AUTOSAR XML (schema 00047)
package /Svc_IoHwAb/ClientServerInterfaces
  5 x client server interface, all with is-service=true:
    IoHwAb_If_AnaInDir
      operation ReadDirect: possible-error=[E_BUSY, E_SETUP_BUFFER_FAIL, E_WRONG_LENGTH]
        arg Value: type=IoHwAb_ValueType, direction=OUT, server-argument-impl-policy=USE-ARGUMENT-TYPE
        arg AnaInDirLength: type=IoHwAb_LengthType, direction=IN, server-argument-impl-policy=USE-ARGUMENT-TYPE
      error E_BUSY: error-code=4
      error E_SETUP_BUFFER_FAIL: error-code=6
      error E_WRONG_LENGTH: error-code=5
    IoHwAb_If_DigDir
      6 x operation:
        IsInput
          arg blResult: type=IoHwAb_BoolType, direction=OUT, server-argument-impl-policy=USE-ARGUMENT-TYPE
        IsOutput
          arg blResult: type=IoHwAb_BoolType, direction=OUT, server-argument-impl-policy=USE-ARGUMENT-TYPE
        ReadDirect
          arg Level: type=IoHwAb_LevelType, direction=OUT, server-argument-impl-policy=USE-ARGUMENT-TYPE
        SetToInput
        SetToOutput
        WriteDirect
          arg Level: type=IoHwAb_LevelType, direction=IN, server-argument-impl-policy=USE-ARGUMENT-TYPE
    IoHwAb_If_Gpt
      7 x operation:
        DisableNotification: possible-error=IoHwAb_If_Gpt/E_NOT_SUPPORTED
        EnableNotification: possible-error=IoHwAb_If_Gpt/E_NOT_SUPPORTED
        GetTimeElapsed: possible-error=IoHwAb_If_Gpt/E_NOT_SUPPORTED
          arg Value: type=IoHwAb_GptValueType, direction=OUT, server-argument-impl-policy=USE-ARGUMENT-TYPE
        GetTimeRemaining: possible-error=IoHwAb_If_Gpt/E_NOT_SUPPORTED
          arg Value: type=IoHwAb_GptValueType, direction=OUT, server-argument-impl-policy=USE-ARGUMENT-TYPE
        Notification
        StartTimer: possible-error=IoHwAb_If_Gpt/E_NOT_SUPPORTED
          arg Value: type=IoHwAb_GptValueType, direction=IN, server-argument-impl-policy=USE-ARGUMENT-TYPE
        StopTimer: possible-error=IoHwAb_If_Gpt/E_NOT_SUPPORTED
      error E_NOT_SUPPORTED: error-code=10
    IoHwAb_If_Icu
      18 x operation:
        DisableEdgeCount: possible-error=IoHwAb_If_Icu/E_NOT_SUPPORTED
        DisableEdgeDetection: possible-error=IoHwAb_If_Icu/E_NOT_SUPPORTED
        DisableNotification: possible-error=IoHwAb_If_Icu/E_NOT_SUPPORTED
        EnableEdgeCount: possible-error=IoHwAb_If_Icu/E_NOT_SUPPORTED
        EnableEdgeDetection: possible-error=IoHwAb_If_Icu/E_NOT_SUPPORTED
        EnableNotification: possible-error=IoHwAb_If_Icu/E_NOT_SUPPORTED
        GetDutyCycleValues: possible-error=IoHwAb_If_Icu/E_NOT_SUPPORTED
          arg DutyCycle: type=IoHwAb_IcuDutyCycleType, direction=OUT, server-argument-impl-policy=USE-ARGUMENT-TYPE
        GetEdgeNumbers: possible-error=IoHwAb_If_Icu/E_NOT_SUPPORTED
          arg Num: type=IoHwAb_IcuEdgeNumberType, direction=OUT, server-argument-impl-policy=USE-ARGUMENT-TYPE
        GetInputState: possible-error=IoHwAb_If_Icu/E_NOT_SUPPORTED
          arg State: type=IoHwAb_IcuStateType, direction=OUT, server-argument-impl-policy=USE-ARGUMENT-TYPE
        GetTimeElapsed: possible-error=IoHwAb_If_Icu/E_NOT_SUPPORTED
          arg Time: type=IoHwAb_IcuValueType, direction=OUT, server-argument-impl-policy=USE-ARGUMENT-TYPE
        GetTimestampIndex: possible-error=IoHwAb_If_Icu/E_NOT_SUPPORTED
          arg TimestampIdx: type=IoHwAb_IcuIndexType, direction=OUT, server-argument-impl-policy=USE-ARGUMENT-TYPE
        Notification
        ResetEdgeCount: possible-error=IoHwAb_If_Icu/E_NOT_SUPPORTED
        SetActivationCondition: possible-error=IoHwAb_If_Icu/E_NOT_SUPPORTED
          arg Activation: type=IoHwAb_IcuActivationType, direction=IN, server-argument-impl-policy=USE-ARGUMENT-TYPE
        StartSignalMeasurement: possible-error=IoHwAb_If_Icu/E_NOT_SUPPORTED
        StartTimestamp: possible-error=IoHwAb_If_Icu/E_NOT_SUPPORTED
          arg BufPtr: type=IoHwAb_IcuValueType, direction=OUT, server-argument-impl-policy=USE-ARGUMENT-TYPE
          arg BufSize: type=uint16, direction=IN, server-argument-impl-policy=USE-ARGUMENT-TYPE
          arg NotiItv: type=uint16, direction=IN, server-argument-impl-policy=USE-ARGUMENT-TYPE
        StopSignalMeasurement: possible-error=IoHwAb_If_Icu/E_NOT_SUPPORTED
        StopTimestamp: possible-error=IoHwAb_If_Icu/E_NOT_SUPPORTED
      error E_NOT_SUPPORTED: error-code=9
    IoHwAb_If_Pwm
      5 x operation, all with possible-error=IoHwAb_If_Pwm/E_NOT_SUPPORTED:
        DisableNotification
        EnableNotification
          arg NotificationEdge: type=IoHwAb_PwmEdgeType, direction=IN, server-argument-impl-policy=USE-ARGUMENT-TYPE
        SetDutyCycle
          arg Duty: type=uint16, direction=IN, server-argument-impl-policy=USE-ARGUMENT-TYPE
        SetOutputToIdle
        SetPeriodAndDuty
          arg Period: type=IoHwAb_PwmPeriodType, direction=IN, server-argument-impl-policy=USE-ARGUMENT-TYPE
          arg Duty: type=uint16, direction=IN, server-argument-impl-policy=USE-ARGUMENT-TYPE
      error E_NOT_SUPPORTED: error-code=11
package /Svc_IoHwAb/CompuMethods
  compu method IoHwAb_Cm_EdgeEnum: 1=IOHWAB_RISING_EDGE (IoHwAb_RisingEdge), 2=IOHWAB_FALLING_EDGE (IoHwAb_FallingEdge), 3=IOHWAB_BOTH_EDGES (IoHwAb_BothEdges)
package /Svc_IoHwAb/EcuAbstractionSwComponentTypes
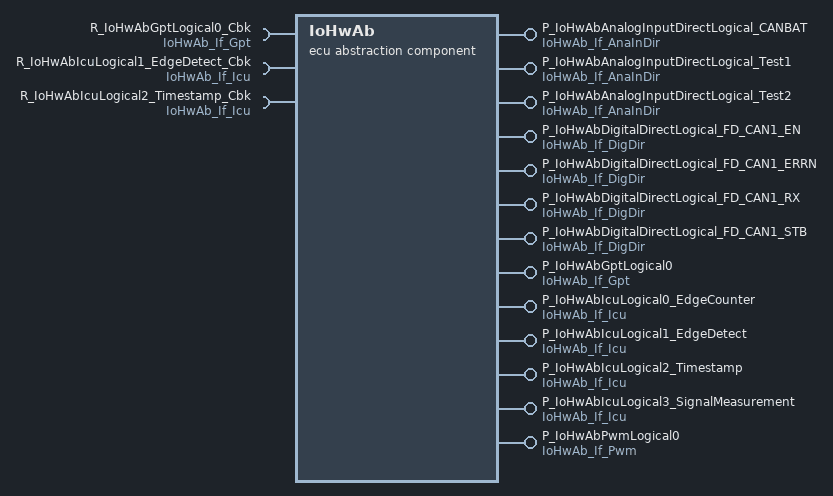
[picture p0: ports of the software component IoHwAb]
  ecu abstraction sw component type IoHwAb
    13 x provide port:
      P_IoHwAbAnalogInputDirectLogical_CANBAT: server-com-spec{operation=IoHwAb_If_AnaInDir/ReadDirect, queue-length=1}, provided-interface=IoHwAb_If_AnaInDir
      P_IoHwAbAnalogInputDirectLogical_Test1: server-com-spec{operation=IoHwAb_If_AnaInDir/ReadDirect, queue-length=1}, provided-interface=IoHwAb_If_AnaInDir
      P_IoHwAbAnalogInputDirectLogical_Test2: server-com-spec{operation=IoHwAb_If_AnaInDir/ReadDirect, queue-length=1}, provided-interface=IoHwAb_If_AnaInDir
      P_IoHwAbDigitalDirectLogical_FD_CAN1_EN: provided-interface=IoHwAb_If_DigDir
        provided-com-specs:
          operation=SetToInput, queue-length=1
          operation=SetToOutput, queue-length=1
          operation=IoHwAb_If_DigDir/ReadDirect, queue-length=1
          operation=WriteDirect, queue-length=1
          operation=IsOutput, queue-length=1
          operation=IsInput, queue-length=1
      P_IoHwAbDigitalDirectLogical_FD_CAN1_ERRN: provided-interface=IoHwAb_If_DigDir
        provided-com-specs:
          operation=SetToInput, queue-length=1
          operation=SetToOutput, queue-length=1
          operation=IoHwAb_If_DigDir/ReadDirect, queue-length=1
          operation=WriteDirect, queue-length=1
          operation=IsOutput, queue-length=1
          operation=IsInput, queue-length=1
      P_IoHwAbDigitalDirectLogical_FD_CAN1_RX: provided-interface=IoHwAb_If_DigDir
        provided-com-specs:
          operation=SetToInput, queue-length=1
          operation=SetToOutput, queue-length=1
          operation=IoHwAb_If_DigDir/ReadDirect, queue-length=1
          operation=WriteDirect, queue-length=1
          operation=IsOutput, queue-length=1
          operation=IsInput, queue-length=1
      P_IoHwAbDigitalDirectLogical_FD_CAN1_STB: provided-interface=IoHwAb_If_DigDir
        provided-com-specs:
          operation=SetToInput, queue-length=1
          operation=SetToOutput, queue-length=1
          operation=IoHwAb_If_DigDir/ReadDirect, queue-length=1
          operation=WriteDirect, queue-length=1
          operation=IsOutput, queue-length=1
          operation=IsInput, queue-length=1
      P_IoHwAbGptLogical0: provided-interface=IoHwAb_If_Gpt
        provided-com-specs:
          operation=StopTimer, queue-length=1
          operation=IoHwAb_If_Gpt/DisableNotification, queue-length=1
          operation=IoHwAb_If_Gpt/GetTimeElapsed, queue-length=1
          operation=IoHwAb_If_Gpt/EnableNotification, queue-length=1
          operation=StartTimer, queue-length=1
          operation=GetTimeRemaining, queue-length=1
      P_IoHwAbIcuLogical0_EdgeCounter: provided-interface=IoHwAb_If_Icu
        provided-com-specs:
          operation=GetInputState, queue-length=1
          operation=IoHwAb_If_Icu/DisableNotification, queue-length=1
          operation=StartTimestamp, queue-length=1
          operation=IoHwAb_If_Icu/GetTimeElapsed, queue-length=1
          operation=DisableEdgeCount, queue-length=1
          operation=EnableEdgeDetection, queue-length=1
          operation=GetDutyCycleValues, queue-length=1
          operation=ResetEdgeCount, queue-length=1
          operation=StopTimestamp, queue-length=1
          operation=StartSignalMeasurement, queue-length=1
          operation=IoHwAb_If_Icu/EnableNotification, queue-length=1
          operation=GetTimestampIndex, queue-length=1
          operation=GetEdgeNumbers, queue-length=1
          operation=DisableEdgeDetection, queue-length=1
          operation=SetActivationCondition, queue-length=1
          operation=EnableEdgeCount, queue-length=1
          operation=StopSignalMeasurement, queue-length=1
      P_IoHwAbIcuLogical1_EdgeDetect: provided-interface=IoHwAb_If_Icu
        provided-com-specs:
          operation=GetInputState, queue-length=1
          operation=IoHwAb_If_Icu/DisableNotification, queue-length=1
          operation=StartTimestamp, queue-length=1
          operation=IoHwAb_If_Icu/GetTimeElapsed, queue-length=1
          operation=DisableEdgeCount, queue-length=1
          operation=EnableEdgeDetection, queue-length=1
          operation=GetDutyCycleValues, queue-length=1
          operation=ResetEdgeCount, queue-length=1
          operation=StopTimestamp, queue-length=1
          operation=StartSignalMeasurement, queue-length=1
          operation=IoHwAb_If_Icu/EnableNotification, queue-length=1
          operation=GetTimestampIndex, queue-length=1
          operation=GetEdgeNumbers, queue-length=1
          operation=DisableEdgeDetection, queue-length=1
          operation=SetActivationCondition, queue-length=1
          operation=EnableEdgeCount, queue-length=1
          operation=StopSignalMeasurement, queue-length=1
      P_IoHwAbIcuLogical2_Timestamp: provided-interface=IoHwAb_If_Icu
        provided-com-specs:
          operation=GetInputState, queue-length=1
          operation=IoHwAb_If_Icu/DisableNotification, queue-length=1
          operation=StartTimestamp, queue-length=1
          operation=IoHwAb_If_Icu/GetTimeElapsed, queue-length=1
          operation=DisableEdgeCount, queue-length=1
          operation=EnableEdgeDetection, queue-length=1
          operation=GetDutyCycleValues, queue-length=1
          operation=ResetEdgeCount, queue-length=1
          operation=StopTimestamp, queue-length=1
          operation=StartSignalMeasurement, queue-length=1
          operation=IoHwAb_If_Icu/EnableNotification, queue-length=1
          operation=GetTimestampIndex, queue-length=1
          operation=GetEdgeNumbers, queue-length=1
          operation=DisableEdgeDetection, queue-length=1
          operation=SetActivationCondition, queue-length=1
          operation=EnableEdgeCount, queue-length=1
          operation=StopSignalMeasurement, queue-length=1
      P_IoHwAbIcuLogical3_SignalMeasurement: provided-interface=IoHwAb_If_Icu
        provided-com-specs:
          operation=GetInputState, queue-length=1
          operation=IoHwAb_If_Icu/DisableNotification, queue-length=1
          operation=StartTimestamp, queue-length=1
          operation=IoHwAb_If_Icu/GetTimeElapsed, queue-length=1
          operation=DisableEdgeCount, queue-length=1
          operation=EnableEdgeDetection, queue-length=1
          operation=GetDutyCycleValues, queue-length=1
          operation=ResetEdgeCount, queue-length=1
          operation=StopTimestamp, queue-length=1
          operation=StartSignalMeasurement, queue-length=1
          operation=IoHwAb_If_Icu/EnableNotification, queue-length=1
          operation=GetTimestampIndex, queue-length=1
          operation=GetEdgeNumbers, queue-length=1
          operation=DisableEdgeDetection, queue-length=1
          operation=SetActivationCondition, queue-length=1
          operation=EnableEdgeCount, queue-length=1
          operation=StopSignalMeasurement, queue-length=1
      P_IoHwAbPwmLogical0: provided-interface=IoHwAb_If_Pwm
        provided-com-specs:
          operation=SetDutyCycle, queue-length=1
          operation=IoHwAb_If_Pwm/DisableNotification, queue-length=1
          operation=SetPeriodAndDuty, queue-length=1
          operation=IoHwAb_If_Pwm/EnableNotification, queue-length=1
          operation=SetOutputToIdle, queue-length=1
    require port R_IoHwAbGptLogical0_Cbk: client-com-spec=IoHwAb_If_Gpt/Notification, required-interface=IoHwAb_If_Gpt
    require port R_IoHwAbIcuLogical1_EdgeDetect_Cbk: client-com-spec=IoHwAb_If_Icu/Notification, required-interface=IoHwAb_If_Icu
    require port R_IoHwAbIcuLogical2_Timestamp_Cbk: client-com-spec=IoHwAb_If_Icu/Notification, required-interface=IoHwAb_If_Icu
    behavior IB_IoHwAb: handle-termination-and-restart=NO-SUPPORT
      106 x operation invoked event:
        IoHwAb_Ev_IoHwAbAnalogInputDirectLogical_CANBAT_ReadDirect: start-on-event=IoHwAb_Re_AnaInDir_ReadDirect, operation=P_IoHwAbAnalogInputDirectLogical_CANBAT.ReadDirect
        IoHwAb_Ev_IoHwAbAnalogInputDirectLogical_Test1_ReadDirect: start-on-event=IoHwAb_Re_AnaInDir_ReadDirect, operation=P_IoHwAbAnalogInputDirectLogical_Test1.ReadDirect
        IoHwAb_Ev_IoHwAbAnalogInputDirectLogical_Test2_ReadDirect: start-on-event=IoHwAb_Re_AnaInDir_ReadDirect, operation=P_IoHwAbAnalogInputDirectLogical_Test2.ReadDirect
        IoHwAb_Ev_IoHwAbDigitalDirectLogical_FD_CAN1_EN_IsInput: start-on-event=IoHwAb_Re_DigDir_IsInput, operation=P_IoHwAbDigitalDirectLogical_FD_CAN1_EN.IsInput
        IoHwAb_Ev_IoHwAbDigitalDirectLogical_FD_CAN1_EN_IsOutput: start-on-event=IoHwAb_Re_DigDir_IsOutput, operation=P_IoHwAbDigitalDirectLogical_FD_CAN1_EN.IsOutput
        IoHwAb_Ev_IoHwAbDigitalDirectLogical_FD_CAN1_EN_ReadDirect: start-on-event=IoHwAb_Re_DigDir_ReadDirect, operation=P_IoHwAbDigitalDirectLogical_FD_CAN1_EN.ReadDirect
        IoHwAb_Ev_IoHwAbDigitalDirectLogical_FD_CAN1_EN_SetToInput: start-on-event=IoHwAb_Re_DigDir_SetToInput, operation=P_IoHwAbDigitalDirectLogical_FD_CAN1_EN.SetToInput
        IoHwAb_Ev_IoHwAbDigitalDirectLogical_FD_CAN1_EN_SetToOutput: start-on-event=IoHwAb_Re_DigDir_SetToOutput, operation=P_IoHwAbDigitalDirectLogical_FD_CAN1_EN.SetToOutput
        IoHwAb_Ev_IoHwAbDigitalDirectLogical_FD_CAN1_EN_WriteDirect: start-on-event=IoHwAb_Re_DigDir_WriteDirect, operation=P_IoHwAbDigitalDirectLogical_FD_CAN1_EN.WriteDirect
        IoHwAb_Ev_IoHwAbDigitalDirectLogical_FD_CAN1_ERRN_IsInput: start-on-event=IoHwAb_Re_DigDir_IsInput, operation=P_IoHwAbDigitalDirectLogical_FD_CAN1_ERRN.IsInput
        IoHwAb_Ev_IoHwAbDigitalDirectLogical_FD_CAN1_ERRN_IsOutput: start-on-event=IoHwAb_Re_DigDir_IsOutput, operation=P_IoHwAbDigitalDirectLogical_FD_CAN1_ERRN.IsOutput
        IoHwAb_Ev_IoHwAbDigitalDirectLogical_FD_CAN1_ERRN_ReadDirect: start-on-event=IoHwAb_Re_DigDir_ReadDirect, operation=P_IoHwAbDigitalDirectLogical_FD_CAN1_ERRN.ReadDirect
        IoHwAb_Ev_IoHwAbDigitalDirectLogical_FD_CAN1_ERRN_SetToInput: start-on-event=IoHwAb_Re_DigDir_SetToInput, operation=P_IoHwAbDigitalDirectLogical_FD_CAN1_ERRN.SetToInput
        IoHwAb_Ev_IoHwAbDigitalDirectLogical_FD_CAN1_ERRN_SetToOutput: start-on-event=IoHwAb_Re_DigDir_SetToOutput, operation=P_IoHwAbDigitalDirectLogical_FD_CAN1_ERRN.SetToOutput
        IoHwAb_Ev_IoHwAbDigitalDirectLogical_FD_CAN1_ERRN_WriteDirect: start-on-event=IoHwAb_Re_DigDir_WriteDirect, operation=P_IoHwAbDigitalDirectLogical_FD_CAN1_ERRN.WriteDirect
        IoHwAb_Ev_IoHwAbDigitalDirectLogical_FD_CAN1_RX_IsInput: start-on-event=IoHwAb_Re_DigDir_IsInput, operation=P_IoHwAbDigitalDirectLogical_FD_CAN1_RX.IsInput
        IoHwAb_Ev_IoHwAbDigitalDirectLogical_FD_CAN1_RX_IsOutput: start-on-event=IoHwAb_Re_DigDir_IsOutput, operation=P_IoHwAbDigitalDirectLogical_FD_CAN1_RX.IsOutput
        IoHwAb_Ev_IoHwAbDigitalDirectLogical_FD_CAN1_RX_ReadDirect: start-on-event=IoHwAb_Re_DigDir_ReadDirect, operation=P_IoHwAbDigitalDirectLogical_FD_CAN1_RX.ReadDirect
        IoHwAb_Ev_IoHwAbDigitalDirectLogical_FD_CAN1_RX_SetToInput: start-on-event=IoHwAb_Re_DigDir_SetToInput, operation=P_IoHwAbDigitalDirectLogical_FD_CAN1_RX.SetToInput
        IoHwAb_Ev_IoHwAbDigitalDirectLogical_FD_CAN1_RX_SetToOutput: start-on-event=IoHwAb_Re_DigDir_SetToOutput, operation=P_IoHwAbDigitalDirectLogical_FD_CAN1_RX.SetToOutput
        IoHwAb_Ev_IoHwAbDigitalDirectLogical_FD_CAN1_RX_WriteDirect: start-on-event=IoHwAb_Re_DigDir_WriteDirect, operation=P_IoHwAbDigitalDirectLogical_FD_CAN1_RX.WriteDirect
        IoHwAb_Ev_IoHwAbDigitalDirectLogical_FD_CAN1_STB_IsInput: start-on-event=IoHwAb_Re_DigDir_IsInput, operation=P_IoHwAbDigitalDirectLogical_FD_CAN1_STB.IsInput
        IoHwAb_Ev_IoHwAbDigitalDirectLogical_FD_CAN1_STB_IsOutput: start-on-event=IoHwAb_Re_DigDir_IsOutput, operation=P_IoHwAbDigitalDirectLogical_FD_CAN1_STB.IsOutput
        IoHwAb_Ev_IoHwAbDigitalDirectLogical_FD_CAN1_STB_ReadDirect: start-on-event=IoHwAb_Re_DigDir_ReadDirect, operation=P_IoHwAbDigitalDirectLogical_FD_CAN1_STB.ReadDirect
        IoHwAb_Ev_IoHwAbDigitalDirectLogical_FD_CAN1_STB_SetToInput: start-on-event=IoHwAb_Re_DigDir_SetToInput, operation=P_IoHwAbDigitalDirectLogical_FD_CAN1_STB.SetToInput
        IoHwAb_Ev_IoHwAbDigitalDirectLogical_FD_CAN1_STB_SetToOutput: start-on-event=IoHwAb_Re_DigDir_SetToOutput, operation=P_IoHwAbDigitalDirectLogical_FD_CAN1_STB.SetToOutput
        IoHwAb_Ev_IoHwAbDigitalDirectLogical_FD_CAN1_STB_WriteDirect: start-on-event=IoHwAb_Re_DigDir_WriteDirect, operation=P_IoHwAbDigitalDirectLogical_FD_CAN1_STB.WriteDirect
        IoHwAb_Ev_IoHwAbGptLogical0_DisableNotification: start-on-event=IoHwAb_Re_Gpt_DisableNotification, operation=P_IoHwAbGptLogical0.DisableNotification
        IoHwAb_Ev_IoHwAbGptLogical0_EnableNotification: start-on-event=IoHwAb_Re_Gpt_EnableNotification, operation=P_IoHwAbGptLogical0.EnableNotification
        IoHwAb_Ev_IoHwAbGptLogical0_GetTimeElapsed: start-on-event=IoHwAb_Re_Gpt_GetTimeElapsed, operation=P_IoHwAbGptLogical0.GetTimeElapsed
        IoHwAb_Ev_IoHwAbGptLogical0_GetTimeRemaining: start-on-event=IoHwAb_Re_Gpt_GetTimeRemaining, operation=P_IoHwAbGptLogical0.GetTimeRemaining
        IoHwAb_Ev_IoHwAbGptLogical0_StartTimer: start-on-event=IoHwAb_Re_Gpt_StartTimer, operation=P_IoHwAbGptLogical0.StartTimer
        IoHwAb_Ev_IoHwAbGptLogical0_StopTimer: start-on-event=IoHwAb_Re_Gpt_StopTimer, operation=P_IoHwAbGptLogical0.StopTimer
        IoHwAb_Ev_IoHwAbIcuLogical0_EdgeCounter_DisableEdgeCount: start-on-event=IoHwAb_Re_Icu_DisableEdgeCount, operation=P_IoHwAbIcuLogical0_EdgeCounter.DisableEdgeCount
        IoHwAb_Ev_IoHwAbIcuLogical0_EdgeCounter_DisableEdgeDetection: start-on-event=IoHwAb_Re_Icu_DisableEdgeDetection, operation=P_IoHwAbIcuLogical0_EdgeCounter.DisableEdgeDetection
        IoHwAb_Ev_IoHwAbIcuLogical0_EdgeCounter_DisableNotification: start-on-event=IoHwAb_Re_Icu_DisableNotification, operation=P_IoHwAbIcuLogical0_EdgeCounter.DisableNotification
        IoHwAb_Ev_IoHwAbIcuLogical0_EdgeCounter_EnableEdgeCount: start-on-event=IoHwAb_Re_Icu_EnableEdgeCount, operation=P_IoHwAbIcuLogical0_EdgeCounter.EnableEdgeCount
        IoHwAb_Ev_IoHwAbIcuLogical0_EdgeCounter_EnableEdgeDetection: start-on-event=IoHwAb_Re_Icu_EnableEdgeDetection, operation=P_IoHwAbIcuLogical0_EdgeCounter.EnableEdgeDetection
        IoHwAb_Ev_IoHwAbIcuLogical0_EdgeCounter_EnableNotification: start-on-event=IoHwAb_Re_Icu_EnableNotification, operation=P_IoHwAbIcuLogical0_EdgeCounter.EnableNotification
        IoHwAb_Ev_IoHwAbIcuLogical0_EdgeCounter_GetDutyCycleValues: start-on-event=IoHwAb_Re_Icu_GetDutyCycleValues, operation=P_IoHwAbIcuLogical0_EdgeCounter.GetDutyCycleValues
        IoHwAb_Ev_IoHwAbIcuLogical0_EdgeCounter_GetEdgeNumbers: start-on-event=IoHwAb_Re_Icu_GetEdgeNumbers, operation=P_IoHwAbIcuLogical0_EdgeCounter.GetEdgeNumbers
        IoHwAb_Ev_IoHwAbIcuLogical0_EdgeCounter_GetInputState: start-on-event=IoHwAb_Re_Icu_GetInputState, operation=P_IoHwAbIcuLogical0_EdgeCounter.GetInputState
        IoHwAb_Ev_IoHwAbIcuLogical0_EdgeCounter_GetTimeElapsed: start-on-event=IoHwAb_Re_Icu_GetTimeElapsed, operation=P_IoHwAbIcuLogical0_EdgeCounter.GetTimeElapsed
        IoHwAb_Ev_IoHwAbIcuLogical0_EdgeCounter_GetTimestampIndex: start-on-event=IoHwAb_Re_Icu_GetTimestampIndex, operation=P_IoHwAbIcuLogical0_EdgeCounter.GetTimestampIndex
        IoHwAb_Ev_IoHwAbIcuLogical0_EdgeCounter_ResetEdgeCount: start-on-event=IoHwAb_Re_Icu_ResetEdgeCount, operation=P_IoHwAbIcuLogical0_EdgeCounter.ResetEdgeCount
        IoHwAb_Ev_IoHwAbIcuLogical0_EdgeCounter_SetActivationCondition: start-on-event=IoHwAb_Re_Icu_SetActivationCondition, operation=P_IoHwAbIcuLogical0_EdgeCounter.SetActivationCondition
        IoHwAb_Ev_IoHwAbIcuLogical0_EdgeCounter_StartSignalMeasurement: start-on-event=IoHwAb_Re_Icu_StartSignalMeasurement, operation=P_IoHwAbIcuLogical0_EdgeCounter.StartSignalMeasurement
        IoHwAb_Ev_IoHwAbIcuLogical0_EdgeCounter_StartTimestamp: start-on-event=IoHwAb_Re_Icu_StartTimestamp, operation=P_IoHwAbIcuLogical0_EdgeCounter.StartTimestamp
        IoHwAb_Ev_IoHwAbIcuLogical0_EdgeCounter_StopSignalMeasurement: start-on-event=IoHwAb_Re_Icu_StopSignalMeasurement, operation=P_IoHwAbIcuLogical0_EdgeCounter.StopSignalMeasurement
        IoHwAb_Ev_IoHwAbIcuLogical0_EdgeCounter_StopTimestamp: start-on-event=IoHwAb_Re_Icu_StopTimestamp, operation=P_IoHwAbIcuLogical0_EdgeCounter.StopTimestamp
        IoHwAb_Ev_IoHwAbIcuLogical1_EdgeDetect_DisableEdgeCount: start-on-event=IoHwAb_Re_Icu_DisableEdgeCount, operation=P_IoHwAbIcuLogical1_EdgeDetect.DisableEdgeCount
        IoHwAb_Ev_IoHwAbIcuLogical1_EdgeDetect_DisableEdgeDetection: start-on-event=IoHwAb_Re_Icu_DisableEdgeDetection, operation=P_IoHwAbIcuLogical1_EdgeDetect.DisableEdgeDetection
        IoHwAb_Ev_IoHwAbIcuLogical1_EdgeDetect_DisableNotification: start-on-event=IoHwAb_Re_Icu_DisableNotification, operation=P_IoHwAbIcuLogical1_EdgeDetect.DisableNotification
        IoHwAb_Ev_IoHwAbIcuLogical1_EdgeDetect_EnableEdgeCount: start-on-event=IoHwAb_Re_Icu_EnableEdgeCount, operation=P_IoHwAbIcuLogical1_EdgeDetect.EnableEdgeCount
        IoHwAb_Ev_IoHwAbIcuLogical1_EdgeDetect_EnableEdgeDetection: start-on-event=IoHwAb_Re_Icu_EnableEdgeDetection, operation=P_IoHwAbIcuLogical1_EdgeDetect.EnableEdgeDetection
        IoHwAb_Ev_IoHwAbIcuLogical1_EdgeDetect_EnableNotification: start-on-event=IoHwAb_Re_Icu_EnableNotification, operation=P_IoHwAbIcuLogical1_EdgeDetect.EnableNotification
        IoHwAb_Ev_IoHwAbIcuLogical1_EdgeDetect_GetDutyCycleValues: start-on-event=IoHwAb_Re_Icu_GetDutyCycleValues, operation=P_IoHwAbIcuLogical1_EdgeDetect.GetDutyCycleValues
        IoHwAb_Ev_IoHwAbIcuLogical1_EdgeDetect_GetEdgeNumbers: start-on-event=IoHwAb_Re_Icu_GetEdgeNumbers, operation=P_IoHwAbIcuLogical1_EdgeDetect.GetEdgeNumbers
        IoHwAb_Ev_IoHwAbIcuLogical1_EdgeDetect_GetInputState: start-on-event=IoHwAb_Re_Icu_GetInputState, operation=P_IoHwAbIcuLogical1_EdgeDetect.GetInputState
        IoHwAb_Ev_IoHwAbIcuLogical1_EdgeDetect_GetTimeElapsed: start-on-event=IoHwAb_Re_Icu_GetTimeElapsed, operation=P_IoHwAbIcuLogical1_EdgeDetect.GetTimeElapsed
        IoHwAb_Ev_IoHwAbIcuLogical1_EdgeDetect_GetTimestampIndex: start-on-event=IoHwAb_Re_Icu_GetTimestampIndex, operation=P_IoHwAbIcuLogical1_EdgeDetect.GetTimestampIndex
        IoHwAb_Ev_IoHwAbIcuLogical1_EdgeDetect_ResetEdgeCount: start-on-event=IoHwAb_Re_Icu_ResetEdgeCount, operation=P_IoHwAbIcuLogical1_EdgeDetect.ResetEdgeCount
        IoHwAb_Ev_IoHwAbIcuLogical1_EdgeDetect_SetActivationCondition: start-on-event=IoHwAb_Re_Icu_SetActivationCondition, operation=P_IoHwAbIcuLogical1_EdgeDetect.SetActivationCondition
        IoHwAb_Ev_IoHwAbIcuLogical1_EdgeDetect_StartSignalMeasurement: start-on-event=IoHwAb_Re_Icu_StartSignalMeasurement, operation=P_IoHwAbIcuLogical1_EdgeDetect.StartSignalMeasurement
        IoHwAb_Ev_IoHwAbIcuLogical1_EdgeDetect_StartTimestamp: start-on-event=IoHwAb_Re_Icu_StartTimestamp, operation=P_IoHwAbIcuLogical1_EdgeDetect.StartTimestamp
        IoHwAb_Ev_IoHwAbIcuLogical1_EdgeDetect_StopSignalMeasurement: start-on-event=IoHwAb_Re_Icu_StopSignalMeasurement, operation=P_IoHwAbIcuLogical1_EdgeDetect.StopSignalMeasurement
        IoHwAb_Ev_IoHwAbIcuLogical1_EdgeDetect_StopTimestamp: start-on-event=IoHwAb_Re_Icu_StopTimestamp, operation=P_IoHwAbIcuLogical1_EdgeDetect.StopTimestamp
        IoHwAb_Ev_IoHwAbIcuLogical2_Timestamp_DisableEdgeCount: start-on-event=IoHwAb_Re_Icu_DisableEdgeCount, operation=P_IoHwAbIcuLogical2_Timestamp.DisableEdgeCount
        IoHwAb_Ev_IoHwAbIcuLogical2_Timestamp_DisableEdgeDetection: start-on-event=IoHwAb_Re_Icu_DisableEdgeDetection, operation=P_IoHwAbIcuLogical2_Timestamp.DisableEdgeDetection
        IoHwAb_Ev_IoHwAbIcuLogical2_Timestamp_DisableNotification: start-on-event=IoHwAb_Re_Icu_DisableNotification, operation=P_IoHwAbIcuLogical2_Timestamp.DisableNotification
        IoHwAb_Ev_IoHwAbIcuLogical2_Timestamp_EnableEdgeCount: start-on-event=IoHwAb_Re_Icu_EnableEdgeCount, operation=P_IoHwAbIcuLogical2_Timestamp.EnableEdgeCount
        IoHwAb_Ev_IoHwAbIcuLogical2_Timestamp_EnableEdgeDetection: start-on-event=IoHwAb_Re_Icu_EnableEdgeDetection, operation=P_IoHwAbIcuLogical2_Timestamp.EnableEdgeDetection
        IoHwAb_Ev_IoHwAbIcuLogical2_Timestamp_EnableNotification: start-on-event=IoHwAb_Re_Icu_EnableNotification, operation=P_IoHwAbIcuLogical2_Timestamp.EnableNotification
        IoHwAb_Ev_IoHwAbIcuLogical2_Timestamp_GetDutyCycleValues: start-on-event=IoHwAb_Re_Icu_GetDutyCycleValues, operation=P_IoHwAbIcuLogical2_Timestamp.GetDutyCycleValues
        IoHwAb_Ev_IoHwAbIcuLogical2_Timestamp_GetEdgeNumbers: start-on-event=IoHwAb_Re_Icu_GetEdgeNumbers, operation=P_IoHwAbIcuLogical2_Timestamp.GetEdgeNumbers
        IoHwAb_Ev_IoHwAbIcuLogical2_Timestamp_GetInputState: start-on-event=IoHwAb_Re_Icu_GetInputState, operation=P_IoHwAbIcuLogical2_Timestamp.GetInputState
        IoHwAb_Ev_IoHwAbIcuLogical2_Timestamp_GetTimeElapsed: start-on-event=IoHwAb_Re_Icu_GetTimeElapsed, operation=P_IoHwAbIcuLogical2_Timestamp.GetTimeElapsed
        IoHwAb_Ev_IoHwAbIcuLogical2_Timestamp_GetTimestampIndex: start-on-event=IoHwAb_Re_Icu_GetTimestampIndex, operation=P_IoHwAbIcuLogical2_Timestamp.GetTimestampIndex
        IoHwAb_Ev_IoHwAbIcuLogical2_Timestamp_ResetEdgeCount: start-on-event=IoHwAb_Re_Icu_ResetEdgeCount, operation=P_IoHwAbIcuLogical2_Timestamp.ResetEdgeCount
        IoHwAb_Ev_IoHwAbIcuLogical2_Timestamp_SetActivationCondition: start-on-event=IoHwAb_Re_Icu_SetActivationCondition, operation=P_IoHwAbIcuLogical2_Timestamp.SetActivationCondition
        IoHwAb_Ev_IoHwAbIcuLogical2_Timestamp_StartSignalMeasurement: start-on-event=IoHwAb_Re_Icu_StartSignalMeasurement, operation=P_IoHwAbIcuLogical2_Timestamp.StartSignalMeasurement
        IoHwAb_Ev_IoHwAbIcuLogical2_Timestamp_StartTimestamp: start-on-event=IoHwAb_Re_Icu_StartTimestamp, operation=P_IoHwAbIcuLogical2_Timestamp.StartTimestamp
        IoHwAb_Ev_IoHwAbIcuLogical2_Timestamp_StopSignalMeasurement: start-on-event=IoHwAb_Re_Icu_StopSignalMeasurement, operation=P_IoHwAbIcuLogical2_Timestamp.StopSignalMeasurement
        IoHwAb_Ev_IoHwAbIcuLogical2_Timestamp_StopTimestamp: start-on-event=IoHwAb_Re_Icu_StopTimestamp, operation=P_IoHwAbIcuLogical2_Timestamp.StopTimestamp
        IoHwAb_Ev_IoHwAbIcuLogical3_SignalMeasurement_DisableEdgeCount: start-on-event=IoHwAb_Re_Icu_DisableEdgeCount, operation=P_IoHwAbIcuLogical3_SignalMeasurement.DisableEdgeCount
        IoHwAb_Ev_IoHwAbIcuLogical3_SignalMeasurement_DisableEdgeDetection: start-on-event=IoHwAb_Re_Icu_DisableEdgeDetection, operation=P_IoHwAbIcuLogical3_SignalMeasurement.DisableEdgeDetection
        IoHwAb_Ev_IoHwAbIcuLogical3_SignalMeasurement_DisableNotification: start-on-event=IoHwAb_Re_Icu_DisableNotification, operation=P_IoHwAbIcuLogical3_SignalMeasurement.DisableNotification
        IoHwAb_Ev_IoHwAbIcuLogical3_SignalMeasurement_EnableEdgeCount: start-on-event=IoHwAb_Re_Icu_EnableEdgeCount, operation=P_IoHwAbIcuLogical3_SignalMeasurement.EnableEdgeCount
        IoHwAb_Ev_IoHwAbIcuLogical3_SignalMeasurement_EnableEdgeDetection: start-on-event=IoHwAb_Re_Icu_EnableEdgeDetection, operation=P_IoHwAbIcuLogical3_SignalMeasurement.EnableEdgeDetection
        IoHwAb_Ev_IoHwAbIcuLogical3_SignalMeasurement_EnableNotification: start-on-event=IoHwAb_Re_Icu_EnableNotification, operation=P_IoHwAbIcuLogical3_SignalMeasurement.EnableNotification
        IoHwAb_Ev_IoHwAbIcuLogical3_SignalMeasurement_GetDutyCycleValues: start-on-event=IoHwAb_Re_Icu_GetDutyCycleValues, operation=P_IoHwAbIcuLogical3_SignalMeasurement.GetDutyCycleValues
        IoHwAb_Ev_IoHwAbIcuLogical3_SignalMeasurement_GetEdgeNumbers: start-on-event=IoHwAb_Re_Icu_GetEdgeNumbers, operation=P_IoHwAbIcuLogical3_SignalMeasurement.GetEdgeNumbers
        IoHwAb_Ev_IoHwAbIcuLogical3_SignalMeasurement_GetInputState: start-on-event=IoHwAb_Re_Icu_GetInputState, operation=P_IoHwAbIcuLogical3_SignalMeasurement.GetInputState
        IoHwAb_Ev_IoHwAbIcuLogical3_SignalMeasurement_GetTimeElapsed: start-on-event=IoHwAb_Re_Icu_GetTimeElapsed, operation=P_IoHwAbIcuLogical3_SignalMeasurement.GetTimeElapsed
        IoHwAb_Ev_IoHwAbIcuLogical3_SignalMeasurement_GetTimestampIndex: start-on-event=IoHwAb_Re_Icu_GetTimestampIndex, operation=P_IoHwAbIcuLogical3_SignalMeasurement.GetTimestampIndex
        IoHwAb_Ev_IoHwAbIcuLogical3_SignalMeasurement_ResetEdgeCount: start-on-event=IoHwAb_Re_Icu_ResetEdgeCount, operation=P_IoHwAbIcuLogical3_SignalMeasurement.ResetEdgeCount
        IoHwAb_Ev_IoHwAbIcuLogical3_SignalMeasurement_SetActivationCondition: start-on-event=IoHwAb_Re_Icu_SetActivationCondition, operation=P_IoHwAbIcuLogical3_SignalMeasurement.SetActivationCondition
        IoHwAb_Ev_IoHwAbIcuLogical3_SignalMeasurement_StartSignalMeasurement: start-on-event=IoHwAb_Re_Icu_StartSignalMeasurement, operation=P_IoHwAbIcuLogical3_SignalMeasurement.StartSignalMeasurement
        IoHwAb_Ev_IoHwAbIcuLogical3_SignalMeasurement_StartTimestamp: start-on-event=IoHwAb_Re_Icu_StartTimestamp, operation=P_IoHwAbIcuLogical3_SignalMeasurement.StartTimestamp
        IoHwAb_Ev_IoHwAbIcuLogical3_SignalMeasurement_StopSignalMeasurement: start-on-event=IoHwAb_Re_Icu_StopSignalMeasurement, operation=P_IoHwAbIcuLogical3_SignalMeasurement.StopSignalMeasurement
        IoHwAb_Ev_IoHwAbIcuLogical3_SignalMeasurement_StopTimestamp: start-on-event=IoHwAb_Re_Icu_StopTimestamp, operation=P_IoHwAbIcuLogical3_SignalMeasurement.StopTimestamp
        IoHwAb_Ev_IoHwAbPwmLogical0_DisableNotification: start-on-event=IoHwAb_Re_Pwm_DisableNotification, operation=P_IoHwAbPwmLogical0.DisableNotification
        IoHwAb_Ev_IoHwAbPwmLogical0_EnableNotification: start-on-event=IoHwAb_Re_Pwm_EnableNotification, operation=P_IoHwAbPwmLogical0.EnableNotification
        IoHwAb_Ev_IoHwAbPwmLogical0_SetDutyCycle: start-on-event=IoHwAb_Re_Pwm_SetDutyCycle, operation=P_IoHwAbPwmLogical0.SetDutyCycle
        IoHwAb_Ev_IoHwAbPwmLogical0_SetOutputToIdle: start-on-event=IoHwAb_Re_Pwm_SetOutputToIdle, operation=P_IoHwAbPwmLogical0.SetOutputToIdle
        IoHwAb_Ev_IoHwAbPwmLogical0_SetPeriodAndDuty: start-on-event=IoHwAb_Re_Pwm_SetPeriodAndDuty, operation=P_IoHwAbPwmLogical0.SetPeriodAndDuty
      port-api-options:
        {enable-take-address=false, indirect-api=false, port-defined-argument-value{value=0, value-type=IoHwAb_IndexType}, port=P_IoHwAbDigitalDirectLogical_FD_CAN1_EN}
        {enable-take-address=false, indirect-api=false, port-defined-argument-value{value=1, value-type=IoHwAb_IndexType}, port=P_IoHwAbDigitalDirectLogical_FD_CAN1_ERRN}
        {enable-take-address=false, indirect-api=false, port-defined-argument-value{value=2, value-type=IoHwAb_IndexType}, port=P_IoHwAbDigitalDirectLogical_FD_CAN1_RX}
        {enable-take-address=false, indirect-api=false, port-defined-argument-value{value=3, value-type=IoHwAb_IndexType}, port=P_IoHwAbDigitalDirectLogical_FD_CAN1_STB}
        {enable-take-address=false, indirect-api=false, port-defined-argument-value{value=0, value-type=IoHwAb_IndexType}, port=P_IoHwAbAnalogInputDirectLogical_CANBAT}
        {enable-take-address=false, indirect-api=false, port-defined-argument-value{value=1, value-type=IoHwAb_IndexType}, port=P_IoHwAbAnalogInputDirectLogical_Test1}
        {enable-take-address=false, indirect-api=false, port-defined-argument-value{value=2, value-type=IoHwAb_IndexType}, port=P_IoHwAbAnalogInputDirectLogical_Test2}
        {enable-take-address=false, indirect-api=false, port-defined-argument-value{value=0, value-type=IoHwAb_IndexType}, port=P_IoHwAbIcuLogical0_EdgeCounter}
        {enable-take-address=false, indirect-api=false, port-defined-argument-value{value=1, value-type=IoHwAb_IndexType}, port=P_IoHwAbIcuLogical1_EdgeDetect}
        {enable-take-address=false, indirect-api=false, port-defined-argument-value{value=2, value-type=IoHwAb_IndexType}, port=P_IoHwAbIcuLogical2_Timestamp}
        {enable-take-address=false, indirect-api=false, port-defined-argument-value{value=3, value-type=IoHwAb_IndexType}, port=P_IoHwAbIcuLogical3_SignalMeasurement}
        {enable-take-address=false, indirect-api=false, port-defined-argument-value{value=0, value-type=IoHwAb_IndexType}, port=P_IoHwAbGptLogical0}
        {enable-take-address=false, indirect-api=false, port-defined-argument-value{value=0, value-type=IoHwAb_IndexType}, port=P_IoHwAbPwmLogical0}
      38 x runnable:
        IoHwAb_Re_AnaInDir_ReadDirect: symbol=IoHwAb_AnaInDirReadDirect
        IoHwAb_Re_DigDir_IsInput: can-be-invoked-concurrently=true, symbol=IoHwAb_DigDirIsInput
        IoHwAb_Re_DigDir_IsOutput: can-be-invoked-concurrently=true, symbol=IoHwAb_DigDirIsOutput
        IoHwAb_Re_DigDir_ReadDirect: can-be-invoked-concurrently=true, symbol=IoHwAb_DigDirReadDirect
        IoHwAb_Re_DigDir_SetToInput: can-be-invoked-concurrently=true, symbol=IoHwAb_DigDirSetToInput
        IoHwAb_Re_DigDir_SetToOutput: can-be-invoked-concurrently=true, symbol=IoHwAb_DigDirSetToOutput
        IoHwAb_Re_DigDir_WriteDirect: can-be-invoked-concurrently=true, symbol=IoHwAb_DigDirWriteDirect
        IoHwAb_Re_Gpt_DisableNotification: can-be-invoked-concurrently=true, symbol=IoHwAb_GptDisableNotification
        IoHwAb_Re_Gpt_EnableNotification: can-be-invoked-concurrently=true, symbol=IoHwAb_GptEnableNotification
        IoHwAb_Re_Gpt_GetTimeElapsed: can-be-invoked-concurrently=true, symbol=IoHwAb_GptGetTimeElapsed
        IoHwAb_Re_Gpt_GetTimeRemaining: can-be-invoked-concurrently=true, symbol=IoHwAb_GptGetTimeRemaining
        IoHwAb_Re_Gpt_GptChannelConfiguration_IoHwAbTest_Cbk_Cbk: can-be-invoked-concurrently=true, symbol=GptChannelConfiguration_IoHwAbTest_Cbk
          sync call IoHwAb_Cp_Gpt_IoHwAbGptLogical0_Cbk: operation=R_IoHwAbGptLogical0_Cbk.Notification
        IoHwAb_Re_Gpt_StartTimer: can-be-invoked-concurrently=true, symbol=IoHwAb_GptStartTimer
        IoHwAb_Re_Gpt_StopTimer: can-be-invoked-concurrently=true, symbol=IoHwAb_GptStopTimer
        IoHwAb_Re_Icu_DisableEdgeCount: can-be-invoked-concurrently=true, symbol=IoHwAb_IcuDisableEdgeCount
        IoHwAb_Re_Icu_DisableEdgeDetection: can-be-invoked-concurrently=true, symbol=IoHwAb_IcuDisableEdgeDetection
        IoHwAb_Re_Icu_DisableNotification: can-be-invoked-concurrently=true, symbol=IoHwAb_IcuDisableNotification
        IoHwAb_Re_Icu_EnableEdgeCount: can-be-invoked-concurrently=true, symbol=IoHwAb_IcuEnableEdgeCount
        IoHwAb_Re_Icu_EnableEdgeDetection: can-be-invoked-concurrently=true, symbol=IoHwAb_IcuEnableEdgeDetection
        IoHwAb_Re_Icu_EnableNotification: can-be-invoked-concurrently=true, symbol=IoHwAb_IcuEnableNotification
        IoHwAb_Re_Icu_GetDutyCycleValues: can-be-invoked-concurrently=true, symbol=IoHwAb_IcuGetDutyCycleValues
        IoHwAb_Re_Icu_GetEdgeNumbers: can-be-invoked-concurrently=true, symbol=IoHwAb_IcuGetEdgeNumbers
        IoHwAb_Re_Icu_GetInputState: can-be-invoked-concurrently=true, symbol=IoHwAb_IcuGetInputState
        IoHwAb_Re_Icu_GetTimeElapsed: can-be-invoked-concurrently=true, symbol=IoHwAb_IcuGetTimeElapsed
        IoHwAb_Re_Icu_GetTimestampIndex: can-be-invoked-concurrently=true, symbol=IoHwAb_IcuGetTimestampIndex
        IoHwAb_Re_Icu_IcuSignalEdgeDetection_Cbk_Cbk: can-be-invoked-concurrently=true, symbol=IcuSignalEdgeDetection_Cbk
          sync call IoHwAb_Cp_Icu_IoHwAbIcuLogical1_EdgeDetect_Cbk: operation=R_IoHwAbIcuLogical1_EdgeDetect_Cbk.Notification, timeout=0.0
        IoHwAb_Re_Icu_IcuTimestampMeasurement_Cbk_Cbk: can-be-invoked-concurrently=true, symbol=IcuTimestampMeasurement_Cbk
          sync call IoHwAb_Cp_Icu_IoHwAbIcuLogical2_Timestamp_Cbk: operation=R_IoHwAbIcuLogical2_Timestamp_Cbk.Notification, timeout=0.0
        IoHwAb_Re_Icu_ResetEdgeCount: can-be-invoked-concurrently=true, symbol=IoHwAb_IcuResetEdgeCount
        IoHwAb_Re_Icu_SetActivationCondition: can-be-invoked-concurrently=true, symbol=IoHwAb_IcuSetActivationCondition
        IoHwAb_Re_Icu_StartSignalMeasurement: can-be-invoked-concurrently=true, symbol=IoHwAb_IcuStartSignalMeasurement
        IoHwAb_Re_Icu_StartTimestamp: can-be-invoked-concurrently=true, symbol=IoHwAb_IcuStartTimestamp
        IoHwAb_Re_Icu_StopSignalMeasurement: can-be-invoked-concurrently=true, symbol=IoHwAb_IcuStopSignalMeasurement
        IoHwAb_Re_Icu_StopTimestamp: can-be-invoked-concurrently=true, symbol=IoHwAb_IcuStopTimestamp
        IoHwAb_Re_Pwm_DisableNotification: can-be-invoked-concurrently=true, symbol=IoHwAb_PwmDisableNotification
        IoHwAb_Re_Pwm_EnableNotification: can-be-invoked-concurrently=true, symbol=IoHwAb_PwmEnableNotification
        IoHwAb_Re_Pwm_SetDutyCycle: can-be-invoked-concurrently=true, symbol=IoHwAb_PwmSetDutyCycle
        IoHwAb_Re_Pwm_SetOutputToIdle: can-be-invoked-concurrently=true, symbol=IoHwAb_PwmSetOutputToIdle
        IoHwAb_Re_Pwm_SetPeriodAndDuty: can-be-invoked-concurrently=true, symbol=IoHwAb_PwmSetPeriodAndDuty
  swc implementation SwcImplementation_IoHwAb: swc-bsw-mapping=SwcBswMapping_IoHwAb, behavior=IB_IoHwAb
package /Svc_IoHwAb/ImplementationDataTypes
  19 x impl type:
    IoHwAb_BoolType: category=VALUE, base-type=uint8, compu {0=IOHWAB_FALSE (IoHwAb_False), 1=IOHWAB_TRUE (IoHwAb_True)}
    IoHwAb_GptValueType: category=VALUE, base-type=uint32
    IoHwAb_IcuActivationType: category=VALUE, base-type=uint8, compu-method=IoHwAb_Cm_EdgeEnum
    IoHwAb_IcuDutyCycleType: category=STRUCTURE
      element ActiveTime: implementation-data-type=IoHwAb_IcuValueType
      element PeriodTime: implementation-data-type=IoHwAb_IcuValueType
    IoHwAb_IcuEdgeNumberType: category=VALUE, base-type=uint32
    IoHwAb_IcuIndexType: category=VALUE, base-type=uint16
    IoHwAb_IcuStateType: category=VALUE, base-type=uint8, compu {0=IOHWAB_IDLE (IoHwAb_Idle), 1=IOHWAB_ACTIVE (IoHwAb_Active)}
    IoHwAb_IcuValueType: category=VALUE, base-type=uint16
    IoHwAb_IndexType: category=VALUE, base-type=uint16
    IoHwAb_LengthType: category=VALUE, base-type=uint8
    IoHwAb_LevelType: category=VALUE, base-type=uint8, compu {0=IOHWAB_LOW (IoHwAb_Low), 1=IOHWAB_HIGH (IoHwAb_High)}
    IoHwAb_OcuPinActionType: category=VALUE, base-type=uint8
    IoHwAb_OcuPinStateType: category=VALUE, base-type=uint8
    IoHwAb_OcuReturnType: category=VALUE, base-type=uint8
    IoHwAb_OcuValueType: category=VALUE, base-type=uint16
    IoHwAb_PwmEdgeType: category=VALUE, base-type=uint8, compu-method=IoHwAb_Cm_EdgeEnum
    IoHwAb_PwmPeriodType: category=VALUE, base-type=uint32
    IoHwAb_ThresholdType: category=VALUE, base-type=uint8
    IoHwAb_ValueType: category=VALUE, base-type=uint16
